# TM4C1294NCPDT register map
Vendor: Texas Instruments; File version: 2.2.0.295
CPU: CM4 r0p1, little endian, MPU, FPU, 3 interrupt priority bits
Registers are 32-bit, read-write, no defined reset value unless marked. A register's access mark holds for its fields unless they carry their own. Offsets are from the block's base; [hi:lo] are bit positions.

## I2C0 — I2C (I2C0)
Base 0x40020000
Same registers: I2C1 0x40021000, I2C2 0x40022000, I2C3 0x40023000, I2C8 0x400B8000, I2C9 0x400B9000, I2C4 0x400C0000, I2C5 0x400C1000, I2C6 0x400C2000, I2C7 0x400C3000
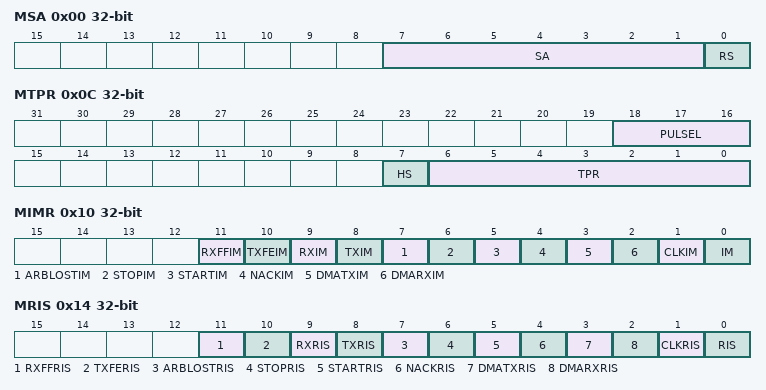
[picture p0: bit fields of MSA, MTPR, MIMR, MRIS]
0x00 MSA
  [7:1] SA — I2C Slave Address
  [0] RS — Receive not send
0x04 MCS
  [31] ACTDMARX — DMA RX Active Status
  [30] ACTDMATX — DMA TX Active Status
  [7] CLKTO — Clock Timeout Error
  [6] BURST — Burst Enable
  [6] BUSBSY — Bus Busy
  [5] IDLE — I2C Idle
  [5] QCMD — Quick Command
  [4] ARBLST — Arbitration Lost
  [4] HS — High-Speed Enable
  [3] ACK — Data Acknowledge Enable
  [3] DATACK — Acknowledge Data
  [2] ADRACK — Acknowledge Address
  [2] STOP — Generate STOP
  [1] ERROR
  [1] START — Generate START
  [0] RUN — I2C Master Enable
  [0] BUSY — I2C Busy
0x08 MDR read-modifies
  [7:0] DATA — This byte contains the data
0x0C MTPR
  [18:16] PULSEL — Glitch Suppression Pulse Width
    0=BYPASS; 1=1 clock; 2=2 clocks; 3=3 clocks; 4=4 clocks; 5=8 clocks; 6=16 clocks; 7=31 clocks
  [7] HS — High-Speed Enable
  [6:0] TPR — Timer Period
0x10 MIMR
  [11] RXFFIM — Receive FIFO Full Interrupt Mask
  [10] TXFEIM — Transmit FIFO Empty Interrupt
  [9] RXIM — Receive FIFO Request Interrupt
  [8] TXIM — Transmit FIFO Request Interrupt
  [7] ARBLOSTIM — Arbitration Lost Interrupt Mask
  [6] STOPIM — STOP Detection Interrupt Mask
  [5] STARTIM — START Detection Interrupt Mask
  [4] NACKIM — Address/Data NACK Interrupt Mask
  [3] DMATXIM — Transmit DMA Interrupt Mask
  [2] DMARXIM — Receive DMA Interrupt Mask
  [1] CLKIM — Clock Timeout Interrupt Mask
  [0] IM — Master Interrupt Mask
0x14 MRIS
  [11] RXFFRIS — Receive FIFO Full Raw Interrupt
  [10] TXFERIS — Transmit FIFO Empty Raw
  [9] RXRIS — Receive FIFO Request Raw
  [8] TXRIS — Transmit Request Raw Interrupt
  [7] ARBLOSTRIS — Arbitration Lost Raw Interrupt
  [6] STOPRIS — STOP Detection Raw Interrupt
  [5] STARTRIS — START Detection Raw Interrupt
  [4] NACKRIS — Address/Data NACK Raw Interrupt
  [3] DMATXRIS — Transmit DMA Raw Interrupt
  [2] DMARXRIS — Receive DMA Raw Interrupt Status
  [1] CLKRIS — Clock Timeout Raw Interrupt
  [0] RIS — Master Raw Interrupt Status
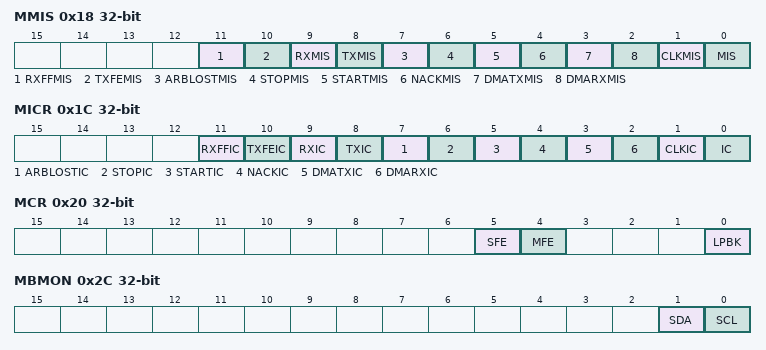
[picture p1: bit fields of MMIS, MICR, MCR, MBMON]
0x18 MMIS
  [11] RXFFMIS — Receive FIFO Full Interrupt Mask
  [10] TXFEMIS — Transmit FIFO Empty Interrupt
  [9] RXMIS — Receive FIFO Request Interrupt
  [8] TXMIS — Transmit Request Interrupt Mask
  [7] ARBLOSTMIS — Arbitration Lost Interrupt Mask
  [6] STOPMIS — STOP Detection Interrupt Mask
  [5] STARTMIS — START Detection Interrupt Mask
  [4] NACKMIS — Address/Data NACK Interrupt Mask
  [3] DMATXMIS — Transmit DMA Interrupt Status
  [2] DMARXMIS — Receive DMA Interrupt Status
  [1] CLKMIS — Clock Timeout Masked Interrupt
  [0] MIS — Masked Interrupt Status
0x1C MICR
  [11] RXFFIC — Receive FIFO Full Interrupt
  [10] TXFEIC — Transmit FIFO Empty Interrupt
  [9] RXIC — Receive FIFO Request Interrupt
  [8] TXIC — Transmit FIFO Request Interrupt
  [7] ARBLOSTIC — Arbitration Lost Interrupt Clear
  [6] STOPIC — STOP Detection Interrupt Clear
  [5] STARTIC — START Detection Interrupt Clear
  [4] NACKIC — Address/Data NACK Interrupt
  [3] DMATXIC — Transmit DMA Interrupt Clear
  [2] DMARXIC — Receive DMA Interrupt Clear
  [1] CLKIC — Clock Timeout Interrupt Clear
  [0] IC — Master Interrupt Clear
0x20 MCR
  [5] SFE — I2C Slave Function Enable
  [4] MFE — I2C Master Function Enable
  [0] LPBK — I2C Loopback
0x24 MCLKOCNT
  [7:0] CNTL — I2C Master Count
0x2C MBMON
  [1] SDA — I2C SDA Status
  [0] SCL — I2C SCL Status
0x30 MBLEN
  [7:0] CNTL — I2C Burst Length
0x34 MBCNT
  [7:0] CNTL — I2C Master Burst Count
0x800 SOAR
  [6:0] OAR — I2C Slave Own Address
0x804 SCSR
  [31] ACTDMARX — DMA RX Active Status
  [30] ACTDMATX — DMA TX Active Status
  [5] QCMDRW — Quick Command Read / Write
  [4] QCMDST — Quick Command Status
  [3] OAR2SEL — OAR2 Address Matched
  [2] FBR — First Byte Received
  [2] RXFIFO — RX FIFO Enable
  [1] TXFIFO — TX FIFO Enable
  [1] TREQ — Transmit Request
  [0] DA — Device Active
  [0] RREQ — Receive Request
0x808 SDR read-modifies
  [7:0] DATA — Data for Transfer
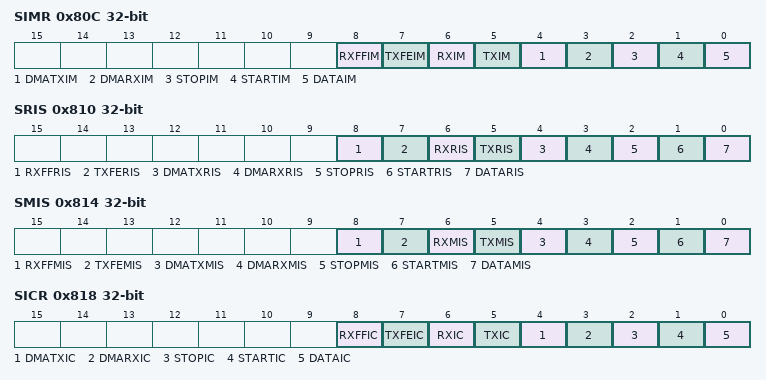
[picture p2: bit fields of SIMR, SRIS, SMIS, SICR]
0x80C SIMR
  [8] RXFFIM — Receive FIFO Full Interrupt Mask
  [7] TXFEIM — Transmit FIFO Empty Interrupt
  [6] RXIM — Receive FIFO Request Interrupt
  [5] TXIM — Transmit FIFO Request Interrupt
  [4] DMATXIM — Transmit DMA Interrupt Mask
  [3] DMARXIM — Receive DMA Interrupt Mask
  [2] STOPIM — Stop Condition Interrupt Mask
  [1] STARTIM — Start Condition Interrupt Mask
  [0] DATAIM — Data Interrupt Mask
0x810 SRIS
  [8] RXFFRIS — Receive FIFO Full Raw Interrupt
  [7] TXFERIS — Transmit FIFO Empty Raw
  [6] RXRIS — Receive FIFO Request Raw
  [5] TXRIS — Transmit Request Raw Interrupt
  [4] DMATXRIS — Transmit DMA Raw Interrupt
  [3] DMARXRIS — Receive DMA Raw Interrupt Status
  [2] STOPRIS — Stop Condition Raw Interrupt
  [1] STARTRIS — Start Condition Raw Interrupt
  [0] DATARIS — Data Raw Interrupt Status
0x814 SMIS
  [8] RXFFMIS — Receive FIFO Full Interrupt Mask
  [7] TXFEMIS — Transmit FIFO Empty Interrupt
  [6] RXMIS — Receive FIFO Request Interrupt
  [5] TXMIS — Transmit FIFO Request Interrupt
  [4] DMATXMIS — Transmit DMA Masked Interrupt
  [3] DMARXMIS — Receive DMA Masked Interrupt
  [2] STOPMIS — Stop Condition Masked Interrupt
  [1] STARTMIS — Start Condition Masked Interrupt
  [0] DATAMIS — Data Masked Interrupt Status
0x818 SICR
  [8] RXFFIC — Receive FIFO Full Interrupt Mask
  [7] TXFEIC — Transmit FIFO Empty Interrupt
  [6] RXIC — Receive Request Interrupt Mask
  [5] TXIC — Transmit Request Interrupt Mask
  [4] DMATXIC — Transmit DMA Interrupt Clear
  [3] DMARXIC — Receive DMA Interrupt Clear
  [2] STOPIC — Stop Condition Interrupt Clear
  [1] STARTIC — Start Condition Interrupt Clear
  [0] DATAIC — Data Interrupt Clear
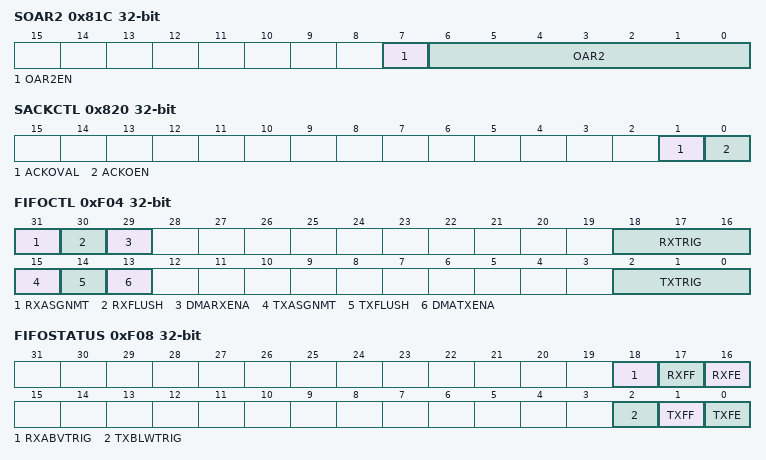
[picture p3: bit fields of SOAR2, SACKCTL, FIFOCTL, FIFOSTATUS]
0x81C SOAR2
  [7] OAR2EN — I2C Slave Own Address 2 Enable
  [6:0] OAR2 — I2C Slave Own Address 2
0x820 SACKCTL
  [1] ACKOVAL — I2C Slave ACK Override Value
  [0] ACKOEN — I2C Slave ACK Override Enable
0xF00 FIFODATA read-modifies
  [7:0] DATA — I2C TX FIFO Write Data Byte
0xF04 FIFOCTL
  [31] RXASGNMT — RX Control Assignment
  [30] RXFLUSH — RX FIFO Flush
  [29] DMARXENA — DMA RX Channel Enable
  [18:16] RXTRIG — RX FIFO Trigger
  [15] TXASGNMT — TX Control Assignment
  [14] TXFLUSH — TX FIFO Flush
  [13] DMATXENA — DMA TX Channel Enable
  [2:0] TXTRIG — TX FIFO Trigger
0xF08 FIFOSTATUS
  [18] RXABVTRIG — RX FIFO Above Trigger Level
  [17] RXFF — RX FIFO Full
  [16] RXFE — RX FIFO Empty
  [2] TXBLWTRIG — TX FIFO Below Trigger Level
  [1] TXFF — TX FIFO Full
  [0] TXFE — TX FIFO Empty
0xFC0 PP
  [0] HS — High-Speed Capable
0xFC4 PC
  [0] HS — High-Speed Capable
